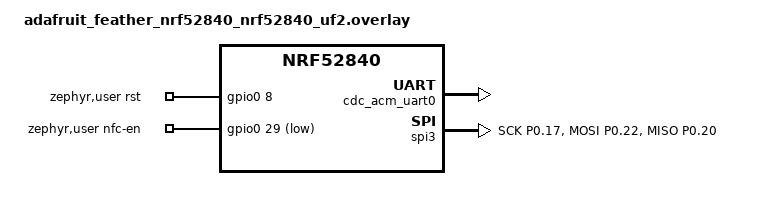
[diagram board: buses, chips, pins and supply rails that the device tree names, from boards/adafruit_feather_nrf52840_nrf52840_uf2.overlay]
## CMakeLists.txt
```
cmake_minimum_required(VERSION 3.20.0)
find_package(Zephyr REQUIRED HINTS $ENV{ZEPHYR_BASE})
project(ntag_writer)
target_sources(app PRIVATE src/main.c src/mfrc522.c)
```

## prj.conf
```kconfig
# NTAG NDEF writer — Elecrow nRF52840 + RC522 scanner board, USB CDC console.
# Build (NCS workspace, same as the scanner):
#   west build -d build_ntag -b adafruit_feather_nrf52840/nrf52840/uf2 tools/ntag-writer
# No Thread, no PM: this is a bench tool that lives on USB.

# Flash layout: app starts at 0x26000 (after Adafruit UF2/SoftDevice bootloader)
CONFIG_USE_DT_CODE_PARTITION=y

CONFIG_SPI=y
CONFIG_GPIO=y

CONFIG_PM=n
CONFIG_PM_DEVICE=n

CONFIG_SERIAL=y
CONFIG_CONSOLE=y
CONFIG_UART_CONSOLE=y
CONFIG_USB_DEVICE_STACK=y
CONFIG_USB_DEVICE_STACK_NEXT=n
CONFIG_USB_CDC_ACM=y
CONFIG_UART_LINE_CTRL=y
CONFIG_USB_DEVICE_PRODUCT="NTAG Writer"
CONFIG_USB_DEVICE_MANUFACTURER="rfid-thread-scanner"

CONFIG_MAIN_STACK_SIZE=4096

# The Elecrow clone may not have a 32 kHz crystal; the scanner builds never
# rely on one (MPSL clock control). Use the RC oscillator.
CONFIG_CLOCK_CONTROL_NRF_K32SRC_RC=y
```

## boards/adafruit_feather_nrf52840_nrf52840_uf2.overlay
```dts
/*
 * Elecrow Pro Micro nRF52840 scanner board, NTAG-writer subset of the main
 * scanner overlay (boards/ in the repo root):
 *   RC522:   SCK->P0.17  MOSI->P0.22  MISO->P0.20  CS->P0.09  RST->P0.08
 *   NFC-EN:  P0.29 (P-channel MOSFET, drive LOW = ON)
 * Console is USB CDC-ACM.
 */
#include <zephyr/dt-bindings/pinctrl/nrf-pinctrl.h>
#include <zephyr/dt-bindings/gpio/gpio.h>

/ {
	chosen {
		zephyr,console    = &cdc_acm_uart0;
		zephyr,shell-uart = &cdc_acm_uart0;
	};

	zephyr,user {
		rst-gpios    = <&gpio0  8 GPIO_ACTIVE_HIGH>;
		nfc-en-gpios = <&gpio0 29 GPIO_ACTIVE_LOW>;
	};
};

&zephyr_udc0 {
	cdc_acm_uart0: cdc_acm_uart0 {
		compatible = "zephyr,cdc-acm-uart";
	};
};

&qspi {
	status = "disabled";
};

&pinctrl {
	spi3_default: spi3_default {
		group1 {
			psels = <NRF_PSEL(SPIM_SCK,  0, 17)>,
				<NRF_PSEL(SPIM_MOSI, 0, 22)>,
				<NRF_PSEL(SPIM_MISO, 0, 20)>;
		};
	};
	spi3_sleep: spi3_sleep {
		group1 {
			psels = <NRF_PSEL(SPIM_SCK,  0, 17)>,
				<NRF_PSEL(SPIM_MOSI, 0, 22)>,
				<NRF_PSEL(SPIM_MISO, 0, 20)>;
			low-power-enable;
		};
	};
};

&spi3 {
	compatible = "nordic,nrf-spim";
	status = "okay";
	pinctrl-0 = <&spi3_default>;
	pinctrl-1 = <&spi3_sleep>;
	pinctrl-names = "default", "sleep";
	cs-gpios = <&gpio0 9 GPIO_ACTIVE_LOW>;
};

/* P0.09 is the RC522 CS; free the NFCT pins for GPIO (writes UICR once). */
&uicr {
	nfct-pins-as-gpios;
};

/* The Feather board dts enables spi1 with the legacy nrfx_spi driver, which
 * conflicts with USB CDC on this board (see the main overlay). Not used here. */
&spi1 {
	status = "disabled";
};

/* The board dts also adds a CDC-ACM port of its own (board_cdc_acm_uart),
 * which enumerates ahead of ours as ttyACM0. Drop it so there is one port.
 * (Takes effect on the next build/flash; v2 still has both.) */
&board_cdc_acm_uart {
	status = "disabled";
};
```

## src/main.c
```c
/*
 * NTAG NDEF-URL writer for the Elecrow nRF52840 + RC522 scanner board.
 *
 * Bench tool: sits on USB CDC-ACM, takes a URL over the console, and writes
 * an NDEF URI record onto every NTAG213/215/216 (or MIFARE Ultralight) tag
 * that is presented. Phones open the URL on tap. Not a Thread build.
 *
 * Console protocol (line based, machine-friendly first token):
 *   url <text>   set the URL           -> OK url=.. ndef=N fits213=y|n
 *   w            arm one write         -> WROTE uid=.. | ERR ..
 *   wl           write every tag       -> WROTE .. per tag, until 'x'
 *   r            read next tag         -> TAG .. / URL ..
 *   rl           read every tag
 *   f            force-format CC only  -> FORMATTED ..
 *   x            disarm
 *   s            status
 *   ?            help
 */
#include <zephyr/kernel.h>
#include <zephyr/drivers/spi.h>
#include <zephyr/drivers/gpio.h>
#include <zephyr/drivers/uart.h>
#include <zephyr/usb/usb_device.h>
#include <zephyr/sys/printk.h>
#include <string.h>
#include <ctype.h>
#include <stdio.h>
#include "mfrc522.h"

#define FW_VERSION      "1"
#define SPI_NODE        DT_NODELABEL(spi3)
#define POLL_MS         100
#define URL_MAX         200
#define NDEF_MAX        (URL_MAX + 16)
#define USER_PAGE0      4          /* Type 2 user memory starts at page 4 */
#define NTAG_MAX_USER   888        /* NTAG216 */

/* ── Hardware ────────────────────────────────────────────────────────────── */

static struct mfrc522_dev rc522 = {
	.spi = NULL,
	.spi_cfg = {
		.frequency = 1000000,
		.operation = SPI_WORD_SET(8) | SPI_TRANSFER_MSB | SPI_OP_MODE_MASTER,
	},
	.cs  = GPIO_DT_SPEC_GET_BY_IDX(DT_NODELABEL(spi3), cs_gpios, 0),
	.rst = GPIO_DT_SPEC_GET(DT_PATH(zephyr_user), rst_gpios),
};

static const struct gpio_dt_spec nfc_en =
	GPIO_DT_SPEC_GET(DT_PATH(zephyr_user), nfc_en_gpios);

static const struct device *usb_uart_dev;
static bool rc522_ok;

/* ── State ───────────────────────────────────────────────────────────────── */

enum mode { MODE_IDLE, MODE_WRITE, MODE_WRITE_LOOP, MODE_READ, MODE_READ_LOOP, MODE_FORMAT };
static enum mode mode = MODE_IDLE;
static char url[URL_MAX + 1];
static uint8_t ndef[NDEF_MAX];
static size_t ndef_len;
static unsigned writes_ok, writes_err;

static const char *mode_name(enum mode m)
{
	switch (m) {
	case MODE_IDLE:       return "idle";
	case MODE_WRITE:      return "write-once";
	case MODE_WRITE_LOOP: return "write-loop";
	case MODE_READ:       return "read-once";
	case MODE_READ_LOOP:  return "read-loop";
	case MODE_FORMAT:     return "format";
	}
	return "?";
}

/* ── NDEF ────────────────────────────────────────────────────────────────── */

/* NFC Forum URI record well-known prefixes (longest first so they win). */
static const struct { const char *s; uint8_t code; } uri_prefix[] = {
	{ "https://www.", 0x02 },
	{ "http://www.",  0x01 },
	{ "https://",     0x04 },
	{ "http://",      0x03 },
};

/* Build TLV-wrapped NDEF message with a single URI record. Returns length or -1. */
static int build_ndef(const char *u, uint8_t *out, size_t cap)
{
	uint8_t code = 0x00;
	const char *rest = u;
	for (size_t i = 0; i < ARRAY_SIZE(uri_prefix); i++) {
		size_t n = strlen(uri_prefix[i].s);
		if (strncmp(u, uri_prefix[i].s, n) == 0) {
			code = uri_prefix[i].code;
			rest = u + n;
			break;
		}
	}
	size_t rest_len = strlen(rest);
	size_t payload_len = 1 + rest_len;          /* prefix code + text */
	if (payload_len > 255) return -1;           /* short record only */
	size_t msg_len = 4 + payload_len;           /* hdr, type len, payload len, type */

	size_t p = 0;
	out[p++] = 0x03;                            /* NDEF Message TLV */
	if (msg_len < 0xFF) {
		out[p++] = (uint8_t)msg_len;
	} else {
		out[p++] = 0xFF;
		out[p++] = (uint8_t)(msg_len >> 8);
		out[p++] = (uint8_t)(msg_len & 0xFF);
	}
	if (p + msg_len + 1 > cap) return -1;
	out[p++] = 0xD1;                            /* MB|ME|SR, TNF=well-known */
	out[p++] = 0x01;                            /* type length */
	out[p++] = (uint8_t)payload_len;
	out[p++] = 'U';
	out[p++] = code;
	memcpy(&out[p], rest, rest_len);
	p += rest_len;
	out[p++] = 0xFE;                            /* Terminator TLV */
	return (int)p;
}

/* Parse a URI record out of user memory; returns true and fills `dst`. */
static bool parse_ndef_url(const uint8_t *mem, size_t len, char *dst, size_t cap)
{
	size_t p = 0;
	while (p < len) {
		uint8_t t = mem[p++];
		if (t == 0x00) continue;               /* NULL TLV */
		if (t == 0xFE) return false;           /* terminator */
		if (p >= len) return false;
		size_t l = mem[p++];
		if (l == 0xFF) {
			if (p + 2 > len) return false;
			l = (mem[p] << 8) | mem[p + 1];
			p += 2;
		}
		if (t != 0x03) { p += l; continue; }    /* skip non-NDEF TLV */
		if (p + l > len || l < 5) return false;
		const uint8_t *r = &mem[p];
		uint8_t hdr = r[0];
		if ((hdr & 0x07) != 0x01 || !(hdr & 0x10)) return false; /* well-known, SR */
		uint8_t tl = r[1];
		uint8_t pl = r[2];
		size_t off = 3 + ((hdr & 0x08) ? 1 : 0);      /* IL: id length byte */
		if (off + tl + pl > l || tl != 1 || r[off] != 'U' || pl < 1) return false;
		const uint8_t *pay = &r[off + tl];
		uint8_t code = pay[0];
		const char *pre = "";
		for (size_t i = 0; i < ARRAY_SIZE(uri_prefix); i++) {
			if (uri_prefix[i].code == code) pre = uri_prefix[i].s;
		}
		size_t pn = strlen(pre);
		size_t tn = pl - 1;
		if (pn + tn + 1 > cap) return false;
		memcpy(dst, pre, pn);
		memcpy(dst + pn, pay + 1, tn);
		dst[pn + tn] = '\0';
		return true;
	}
	return false;
}

/* ── Tag helpers ─────────────────────────────────────────────────────────── */

static void print_uid(const struct mfrc522_uid *uid)
{
	for (uint8_t i = 0; i < uid->size; i++) {
		printk("%s%02X", i ? ":" : "", uid->bytes[i]);
	}
}

/* User-memory size in bytes from GET_VERSION, else from the CC, else 48. */
static int tag_user_size(const uint8_t cc[4], const char **name)
{
	uint8_t ver[8];
	*name = "Type2";
	if (mfrc522_ntag_get_version(&rc522, ver) == MFRC_OK && ver[1] == 0x04) {
		switch (ver[6]) {
		case 0x0F: *name = "NTAG213"; return 144;
		case 0x11: *name = "NTAG215"; return 504;
		case 0x13: *name = "NTAG216"; return 888;
		default: break;
		}
	}
	if (cc[0] == 0xE1 && cc[2] != 0) {
		*name = "NDEF-CC";
		int sz = cc[2] * 8;
		return sz > NTAG_MAX_USER ? NTAG_MAX_USER : sz;
	}
	*name = "Ultralight?";
	return 48;
}

static int read_range(uint8_t page0, uint8_t *dst, size_t nbytes)
{
	uint8_t buf[16];
	size_t got = 0;
	uint8_t page = page0;
	while (got < nbytes) {
		int rc = mfrc522_ntag_read(&rc522, page, buf);
		if (rc != MFRC_OK) return rc;
		size_t take = nbytes - got < 16 ? nbytes - got : 16;
		memcpy(dst + got, buf, take);
		got += take;
		page += 4;
	}
	return MFRC_OK;
}

static int write_cc(int user_size)
{
	uint8_t cc[4] = { 0xE1, 0x10, (uint8_t)(user_size / 8), 0x00 };
	return mfrc522_ntag_write(&rc522, 3, cc);
}

/* ── Actions on a selected tag ──────────────────────────────────────────── */

static void do_read(const struct mfrc522_uid *uid)
{
	uint8_t hdr[16];
	if (mfrc522_ntag_read(&rc522, 0, hdr) != MFRC_OK) {
		printk("ERR read header failed\n");
		return;
	}
	const uint8_t *cc = &hdr[12];
	const char *name;
	int user = tag_user_size(cc, &name);
	printk("TAG uid="); print_uid(uid);
	printk(" sak=%02X type=%s user=%d cc=%02X%02X%02X%02X\n",
	       uid->sak, name, user, cc[0], cc[1], cc[2], cc[3]);

	static uint8_t mem[NTAG_MAX_USER];
	size_t n = user < (int)sizeof(mem) ? user : sizeof(mem);
	if (read_range(USER_PAGE0, mem, n) != MFRC_OK) {
		printk("ERR read user memory failed\n");
		return;
	}
	char found[URL_MAX + 1];
	if (parse_ndef_url(mem, n, found, sizeof(found))) {
		printk("URL %s\n", found);
	} else {
		printk("URL (none)\n");
	}
	printk("MEM");
	for (size_t i = 0; i < 32 && i < n; i++) printk(" %02X", mem[i]);
	printk("%s\n", n > 32 ? " ..." : "");
}

static void do_write(const struct mfrc522_uid *uid, bool format_only)
{
	if (uid->sak != 0x00) {
		printk("ERR uid="); print_uid(uid);
		printk(" sak=%02X is not a Type 2 tag (MIFARE Classic?)\n", uid->sak);
		writes_err++;
		return;
	}
	uint8_t hdr[16];
	if (mfrc522_ntag_read(&rc522, 0, hdr) != MFRC_OK) {
		printk("ERR read header failed\n");
		writes_err++;
		return;
	}
	const uint8_t *cc = &hdr[12];
	const char *name;
	int user = tag_user_size(cc, &name);

	if (format_only) {
		if (cc[0] == 0xE1) {
			printk("FORMATTED uid="); print_uid(uid);
			printk(" already (cc=%02X%02X%02X%02X)\n", cc[0], cc[1], cc[2], cc[3]);
			return;
		}
		if (write_cc(user) != MFRC_OK) {
			printk("ERR CC write failed\n");
			return;
		}
		printk("FORMATTED uid="); print_uid(uid);
		printk(" user=%d\n", user);
		return;
	}

	if (ndef_len == 0) {
		printk("ERR no url set\n");
		writes_err++;
		return;
	}
	if ((int)ndef_len > user) {
		printk("ERR ndef %u bytes > %s user %d\n", (unsigned)ndef_len, name, user);
		writes_err++;
		return;
	}
	/* CC is OTP (bits only go 0->1). Only touch it when it is blank. */
	if (cc[0] != 0xE1) {
		if (cc[0] == 0 && cc[1] == 0 && cc[2] == 0 && cc[3] == 0) {
			if (write_cc(user) != MFRC_OK) {
				printk("ERR CC write failed\n");
				writes_err++;
				return;
			}
		} else {
			printk("ERR cc=%02X%02X%02X%02X not NDEF and not blank; refusing\n",
			       cc[0], cc[1], cc[2], cc[3]);
			writes_err++;
			return;
		}
	}

	/* Write pages, zero-padded to a 4-byte boundary. */
	size_t pages = (ndef_len + 3) / 4;
	for (size_t i = 0; i < pages; i++) {
		uint8_t d[4] = { 0, 0, 0, 0 };
		size_t off = i * 4;
		size_t take = ndef_len - off < 4 ? ndef_len - off : 4;
		memcpy(d, &ndef[off], take);
		if (mfrc522_ntag_write(&rc522, USER_PAGE0 + i, d) != MFRC_OK) {
			printk("ERR write page %u failed\n", (unsigned)(USER_PAGE0 + i));
			writes_err++;
			return;
		}
	}

	/* Verify. */
	static uint8_t back[NDEF_MAX + 16];
	size_t vlen = pages * 4;
	if (read_range(USER_PAGE0, back, vlen) != MFRC_OK ||
	    memcmp(back, ndef, ndef_len) != 0) {
		printk("ERR verify mismatch\n");
		writes_err++;
		return;
	}
	writes_ok++;
	printk("WROTE uid="); print_uid(uid);
	printk(" type=%s bytes=%u pages=%u n=%u\n", name, (unsigned)ndef_len,
	       (unsigned)pages, writes_ok);
}

/* ── Console ─────────────────────────────────────────────────────────────── */

static void print_help(void)
{
	printk("commands:\n"
	       "  url <text>  set URL to write\n"
	       "  w           write next tag once\n"
	       "  wl          write every tag until x\n"
	       "  r / rl      read next tag / every tag\n"
	       "  f           format CC on next tag (blank tags only)\n"
	       "  x           disarm\n"
	       "  s           status\n");
}

static void print_status(void)
{
	printk("STATUS mode=%s rc522=%s url=%s ndef=%u ok=%u err=%u\n",
	       mode_name(mode), rc522_ok ? "ok" : "missing",
	       url[0] ? url : "(none)", (unsigned)ndef_len, writes_ok, writes_err);
}

static void handle_cmd(char *line)
{
	/* trim */
	while (*line && isspace((unsigned char)*line)) line++;
	char *end = line + strlen(line);
	while (end > line && isspace((unsigned char)end[-1])) *--end = '\0';
	if (!*line) return;

	if (strncmp(line, "url ", 4) == 0 || strncmp(line, "u ", 2) == 0) {
		const char *arg = line + (line[1] == ' ' ? 2 : 4);
		while (*arg == ' ') arg++;
		if (strlen(arg) > URL_MAX) {
			printk("ERR url longer than %d\n", URL_MAX);
			return;
		}
		int n = build_ndef(arg, ndef, sizeof(ndef));
		if (n < 0) {
			printk("ERR url does not fit an NDEF short record\n");
			return;
		}
		strcpy(url, arg);
		ndef_len = (size_t)n;
		printk("OK url=%s ndef=%u fits213=%c fits215=%c\n", url, (unsigned)ndef_len,
		       ndef_len <= 144 ? 'y' : 'n', ndef_len <= 504 ? 'y' : 'n');
	} else if (strcmp(line, "w") == 0) {
		if (!ndef_len) { printk("ERR no url set\n"); return; }
		mode = MODE_WRITE;  printk("OK armed write-once; present a tag\n");
	} else if (strcmp(line, "wl") == 0) {
		if (!ndef_len) { printk("ERR no url set\n"); return; }
		mode = MODE_WRITE_LOOP; printk("OK armed write-loop; present tags, x to stop\n");
	} else if (strcmp(line, "r") == 0) {
		mode = MODE_READ;   printk("OK armed read-once\n");
	} else if (strcmp(line, "rl") == 0) {
		mode = MODE_READ_LOOP; printk("OK armed read-loop\n");
	} else if (strcmp(line, "f") == 0) {
		mode = MODE_FORMAT; printk("OK armed format-once\n");
	} else if (strcmp(line, "x") == 0) {
		mode = MODE_IDLE;   printk("OK idle\n");
	} else if (strcmp(line, "s") == 0) {
		print_status();
	} else if (strcmp(line, "?") == 0 || strcmp(line, "help") == 0) {
		print_help();
	} else {
		printk("ERR unknown command: %s\n", line);
	}
}

#define CONSOLE_STACK 2048
K_THREAD_STACK_DEFINE(console_stack, CONSOLE_STACK);
static struct k_thread console_thread_data;

static void console_thread(void *a, void *b, void *c)
{
	ARG_UNUSED(a); ARG_UNUSED(b); ARG_UNUSED(c);
	char line[URL_MAX + 8];
	int pos = 0;
	while (1) {
		uint8_t ch;
		if (uart_poll_in(usb_uart_dev, &ch) == 0) {
			if (ch == '\r' || ch == '\n') {
				line[pos] = '\0';
				if (pos > 0) {
					handle_cmd(line);
					pos = 0;
				}
			} else if ((ch == '\b' || ch == 0x7f) && pos > 0) {
				pos--;
			} else if (pos < (int)sizeof(line) - 1 && ch >= 0x20) {
				line[pos++] = ch;
			}
		} else {
			k_sleep(K_MSEC(5));
		}
	}
}

/* ── Main ────────────────────────────────────────────────────────────────── */

int main(void)
{
	rc522.spi = DEVICE_DT_GET(SPI_NODE);
	usb_uart_dev = DEVICE_DT_GET(DT_CHOSEN(zephyr_console));
	usb_enable(NULL);

	/* NFC rail on (P-FET, active low). */
	if (gpio_is_ready_dt(&nfc_en)) {
		gpio_pin_configure_dt(&nfc_en, GPIO_OUTPUT_ACTIVE);
		k_sleep(K_MSEC(20));
	}

	rc522_ok = false;
	if (mfrc522_init(&rc522) == 0) {
		uint8_t ver = mfrc522_read_version(&rc522);
		rc522_ok = (ver != 0x00 && ver != 0xFF);
	}

	k_thread_create(&console_thread_data, console_stack,
			K_THREAD_STACK_SIZEOF(console_stack),
			console_thread, NULL, NULL, NULL,
			K_PRIO_PREEMPT(5), 0, K_NO_WAIT);

	/* Give the host a moment to open the port, then announce. */
	k_sleep(K_SECONDS(2));
	printk("\nREADY ntag-writer v" FW_VERSION " rc522=%s (0x%02X)\n",
	       rc522_ok ? "ok" : "MISSING", mfrc522_read_version(&rc522));
	print_help();

	while (1) {
		if (mode == MODE_IDLE || !rc522_ok) {
			k_sleep(K_MSEC(POLL_MS));
			continue;
		}
		if (!mfrc522_is_card_present(&rc522)) {
			k_sleep(K_MSEC(POLL_MS));
			continue;
		}
		struct mfrc522_uid uid;
		if (mfrc522_read_card_serial(&rc522, &uid) != MFRC_OK) {
			k_sleep(K_MSEC(POLL_MS));
			continue;
		}

		enum mode m = mode;
		switch (m) {
		case MODE_WRITE:
		case MODE_WRITE_LOOP:
			do_write(&uid, false);
			break;
		case MODE_FORMAT:
			do_write(&uid, true);
			break;
		case MODE_READ:
		case MODE_READ_LOOP:
			do_read(&uid);
			break;
		default:
			break;
		}
		/* HLTA: a halted tag ignores REQA, so it is not re-processed until
		 * it leaves the field and comes back. */
		mfrc522_halt(&rc522);

		if (m == MODE_WRITE || m == MODE_READ || m == MODE_FORMAT) {
			mode = MODE_IDLE;
			printk("OK idle\n");
		}
		k_sleep(K_MSEC(300));
	}
	return 0;
}
```

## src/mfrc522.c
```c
#include <string.h>
#include "mfrc522.h"
#include <zephyr/logging/log.h>
LOG_MODULE_REGISTER(mfrc522, LOG_LEVEL_DBG);

/* ── Low-level SPI register access ────────────────────────────────────── */
/* All accessors return 0 or a negative errno from the SPI driver, so a
 * failed bus transaction is distinguishable from a register that
 * legitimately reads 0x00. */

static int reg_write(struct mfrc522_dev *dev, uint8_t reg, uint8_t val)
{
	uint8_t tx[2] = { reg & 0x7E, val };
	struct spi_buf     buf    = { .buf = tx, .len = 2 };
	struct spi_buf_set tx_set = { .buffers = &buf, .count = 1 };
	gpio_pin_set_dt(&dev->cs, 1);  /* assert CS (active-low: logical 1 = physical LOW) */
	int rc = spi_write(dev->spi, &dev->spi_cfg, &tx_set);
	gpio_pin_set_dt(&dev->cs, 0);  /* deassert CS */
	return rc;
}

static int reg_read(struct mfrc522_dev *dev, uint8_t reg, uint8_t *val)
{
	uint8_t tx[2] = { 0x80 | reg, 0 };
	uint8_t rx[2] = { 0, 0 };
	struct spi_buf     tbuf   = { .buf = tx, .len = 2 };
	struct spi_buf     rbuf   = { .buf = rx, .len = 2 };
	struct spi_buf_set tx_set = { .buffers = &tbuf, .count = 1 };
	struct spi_buf_set rx_set = { .buffers = &rbuf, .count = 1 };
	gpio_pin_set_dt(&dev->cs, 1);  /* assert CS */
	int rc = spi_transceive(dev->spi, &dev->spi_cfg, &tx_set, &rx_set);
	gpio_pin_set_dt(&dev->cs, 0);  /* deassert CS */
	*val = rx[1];
	return rc;
}

static int reg_set_bits(struct mfrc522_dev *dev, uint8_t reg, uint8_t mask)
{
	uint8_t val;
	int rc = reg_read(dev, reg, &val);
	if (rc < 0) {
		return rc;
	}
	return reg_write(dev, reg, val | mask);
}

static int reg_clear_bits(struct mfrc522_dev *dev, uint8_t reg, uint8_t mask)
{
	uint8_t val;
	int rc = reg_read(dev, reg, &val);
	if (rc < 0) {
		return rc;
	}
	return reg_write(dev, reg, val & ~mask);
}

static int fifo_write(struct mfrc522_dev *dev, const uint8_t *data, uint8_t len)
{
	for (uint8_t i = 0; i < len; i++) {
		int rc = reg_write(dev, MFRC_FIFODataReg, data[i]);
		if (rc < 0) {
			return rc;
		}
	}
	return 0;
}

/* ── CRC helper ────────────────────────────────────────────────────────── */

static int pcd_calc_crc(struct mfrc522_dev *dev, const uint8_t *data, uint8_t len, uint8_t crc[2])
{
	if (reg_write(dev, MFRC_CommandReg, PCD_Idle) < 0 ||
	    reg_write(dev, MFRC_DivIrqReg, 0x04) < 0 ||       /* clear CRCIRq */
	    reg_set_bits(dev, MFRC_FIFOLevelReg, 0x80) < 0 || /* flush FIFO */
	    fifo_write(dev, data, len) < 0 ||
	    reg_write(dev, MFRC_CommandReg, PCD_CalcCRC) < 0) {
		return MFRC_BUS_ERROR;
	}

	int64_t deadline = k_uptime_get() + 50;
	while (k_uptime_get() < deadline) {
		uint8_t irq;
		if (reg_read(dev, MFRC_DivIrqReg, &irq) < 0) {
			return MFRC_BUS_ERROR;
		}
		if (irq & 0x04) {
			if (reg_write(dev, MFRC_CommandReg, PCD_Idle) < 0 ||
			    reg_read(dev, MFRC_CRCResultRegL, &crc[0]) < 0 ||
			    reg_read(dev, MFRC_CRCResultRegH, &crc[1]) < 0) {
				return MFRC_BUS_ERROR;
			}
			return MFRC_OK;
		}
		k_sleep(K_MSEC(1)); /* yield — don't busy-spin between register reads */
	}
	return MFRC_TIMEOUT;
}

/* ── Transceive ────────────────────────────────────────────────────────── */

static int pcd_transceive(struct mfrc522_dev *dev,
			   const uint8_t *tx_data, uint8_t tx_len,
			   uint8_t *rx_data, uint8_t *rx_len,
			   uint8_t *valid_bits)
{
	if (reg_write(dev, MFRC_CommandReg, PCD_Idle) < 0 ||
	    reg_set_bits(dev, MFRC_FIFOLevelReg, 0x80) < 0 ||
	    fifo_write(dev, tx_data, tx_len) < 0 ||
	    reg_write(dev, MFRC_BitFramingReg, valid_bits ? *valid_bits : 0) < 0 ||
	    /* Clear stale IRQ flags (Set1=0 → clear the bits that are set in bits[6:0]) */
	    reg_write(dev, MFRC_ComIrqReg, 0x7F) < 0 ||
	    reg_write(dev, MFRC_CommandReg, PCD_Transceive) < 0 ||
	    reg_set_bits(dev, MFRC_BitFramingReg, 0x80) < 0) { /* StartSend */
		return MFRC_BUS_ERROR;
	}

	/* Wait for completion (timeout ~25ms via timer config) */
	int64_t deadline = k_uptime_get() + 50;
	uint8_t irq = 0;
	do {
		if (reg_read(dev, MFRC_ComIrqReg, &irq) < 0) {
			return MFRC_BUS_ERROR;
		}
		if (irq & 0x30) break; /* RxIRq or IdleIRq */
		if (irq & 0x01) return MFRC_TIMEOUT; /* TimerIRq */
		k_sleep(K_MSEC(1)); /* yield — don't busy-spin between register reads */
	} while (k_uptime_get() < deadline);

	if (!(irq & 0x30)) return MFRC_TIMEOUT;

	uint8_t err;
	if (reg_read(dev, MFRC_ErrorReg, &err) < 0) {
		return MFRC_BUS_ERROR;
	}
	if (err & 0x13) return MFRC_ERROR; /* BufferOvfl, ParityErr, ProtocolErr */
	if (err & 0x08) return MFRC_COLLISION;

	uint8_t n;
	if (reg_read(dev, MFRC_FIFOLevelReg, &n) < 0) {
		return MFRC_BUS_ERROR;
	}
	if (rx_len && rx_data) {
		uint8_t copy = (n < *rx_len) ? n : *rx_len;
		*rx_len = copy;
		for (uint8_t i = 0; i < copy; i++) {
			if (reg_read(dev, MFRC_FIFODataReg, &rx_data[i]) < 0) {
				return MFRC_BUS_ERROR;
			}
		}
	}
	if (valid_bits) {
		uint8_t ctrl;
		if (reg_read(dev, MFRC_ControlReg, &ctrl) < 0) {
			return MFRC_BUS_ERROR;
		}
		*valid_bits = ctrl & 0x07;
	}
	return MFRC_OK;
}

/* ── Public API ────────────────────────────────────────────────────────── */

int mfrc522_init(struct mfrc522_dev *dev)
{
	if (!device_is_ready(dev->spi)) return -ENODEV;

	/* Configure CS as output deasserted (inactive = physical HIGH for active-low) */
	gpio_pin_configure_dt(&dev->cs, GPIO_OUTPUT_INACTIVE);

	/* Hardware reset via RST pin */
	gpio_pin_configure_dt(&dev->rst, GPIO_OUTPUT_ACTIVE);
	k_sleep(K_MSEC(10));
	gpio_pin_set_dt(&dev->rst, 0);
	k_sleep(K_MSEC(50));
	gpio_pin_set_dt(&dev->rst, 1);
	k_sleep(K_MSEC(50));

	/* Soft reset */
	if (reg_write(dev, MFRC_CommandReg, PCD_SoftReset) < 0) {
		return -EIO;
	}
	k_sleep(K_MSEC(50));

	/* Configure timer: auto, prescaler=169 → ~40kHz, reload=1000 → 25ms */
	if (reg_write(dev, MFRC_TModeReg,      0x80) < 0 ||
	    reg_write(dev, MFRC_TPrescalerReg, 0xA9) < 0 ||
	    reg_write(dev, MFRC_TReloadRegH,   0x03) < 0 ||
	    reg_write(dev, MFRC_TReloadRegL,   0xE8) < 0 ||
	    reg_write(dev, MFRC_TxASKReg, 0x40) < 0 ||  /* 100% ASK */
	    reg_write(dev, MFRC_ModeReg,  0x3D) < 0) {  /* CRC preset 6363h */
		return -EIO;
	}

	/* Antenna on */
	uint8_t tx;
	if (reg_read(dev, MFRC_TxControlReg, &tx) < 0) {
		return -EIO;
	}
	if (!(tx & 0x03)) {
		if (reg_set_bits(dev, MFRC_TxControlReg, 0x03) < 0) {
			return -EIO;
		}
	}
	return 0;
}

uint8_t mfrc522_read_version(struct mfrc522_dev *dev)
{
	uint8_t ver = 0;

	/* A bus error reads as 0x00, which callers already treat as "no reader" */
	if (reg_read(dev, MFRC_VersionReg, &ver) < 0) {
		return 0x00;
	}
	return ver;
}

/* SoftPowerDown: ~26mA antenna current → ~10µA. Antenna also goes off. */
void mfrc522_sleep(struct mfrc522_dev *dev)
{
	reg_clear_bits(dev, MFRC_TxControlReg, 0x03);
	reg_write(dev, MFRC_CommandReg, 0x10 | PCD_Idle);
}

void mfrc522_wake(struct mfrc522_dev *dev)
{
	reg_write(dev, MFRC_CommandReg, PCD_Idle);
	/* Bit clears automatically once oscillator stable; poll briefly */
	for (int i = 0; i < 50; i++) {
		uint8_t cmd;
		if (reg_read(dev, MFRC_CommandReg, &cmd) == 0 && !(cmd & 0x10)) {
			break;
		}
		k_sleep(K_MSEC(1));
	}
	reg_set_bits(dev, MFRC_TxControlReg, 0x03);
}

bool mfrc522_is_card_present(struct mfrc522_dev *dev)
{
	/* Reset baud rates (required before REQA per MFRC522 datasheet) */
	if (reg_write(dev, MFRC_TxModeReg,  0x00) < 0 ||
	    reg_write(dev, MFRC_RxModeReg,  0x00) < 0 ||
	    reg_write(dev, MFRC_ModWidthReg, 0x26) < 0) {
		return false;
	}

	reg_clear_bits(dev, MFRC_CollReg, 0x80);
	uint8_t cmd     = PICC_CMD_REQA;
	uint8_t atqa[2] = { 0, 0 };
	uint8_t atqa_len = 2;
	uint8_t vbits    = 7; /* Short frame: 7 bits */

	int rc = pcd_transceive(dev, &cmd, 1, atqa, &atqa_len, &vbits);
	return (rc == MFRC_OK || rc == MFRC_COLLISION);
}

int mfrc522_read_card_serial(struct mfrc522_dev *dev, struct mfrc522_uid *uid)
{
	/* ISO 14443A anti-collision + SELECT, handles 4-byte and 7-byte UIDs */
	static const uint8_t cl_cmd[2] = { PICC_CMD_ANTICOLL, PICC_CMD_SEL_CL2 };
	uint8_t buf[9];
	uint8_t buf_len, vbits;
	int rc;
	uint8_t uid_idx = 0;

	uid->size = 0;

	for (int cl = 0; cl < 2; cl++) {
		/* Anti-collision */
		reg_clear_bits(dev, MFRC_CollReg, 0x80);
		reg_write(dev, MFRC_BitFramingReg, 0x00);

		buf[0] = cl_cmd[cl];
		buf[1] = 0x20;
		buf_len = 5;
		vbits   = 0;

		rc = pcd_transceive(dev, buf, 2, &buf[2], &buf_len, &vbits);
		if (rc != MFRC_OK && rc != MFRC_COLLISION) return rc;
		if (buf_len < 5) return MFRC_ERROR;

		/* BCC: XOR of all 5 bytes must be 0 */
		if ((buf[2] ^ buf[3] ^ buf[4] ^ buf[5] ^ buf[6]) != 0) return MFRC_ERROR;

		/* SELECT: send [CLx, 0x70, uid0..3, bcc, crc_l, crc_h] */
		buf[1] = 0x70;
		uint8_t crc[2];
		rc = pcd_calc_crc(dev, buf, 7, crc);
		if (rc != MFRC_OK) return rc;
		buf[7] = crc[0];
		buf[8] = crc[1];

		uint8_t sak_buf[3] = {0};
		uint8_t sak_len = 3;
		uint8_t sak_vbits = 0;
		rc = pcd_transceive(dev, buf, 9, sak_buf, &sak_len, &sak_vbits);
		if (rc != MFRC_OK) return rc;

		uint8_t sak = sak_buf[0];
		uid->sak = sak;

		/* Copy UID bytes from this cascade level, skipping cascade tag (0x88) */
		bool has_ct  = (buf[2] == 0x88);
		uint8_t start = has_ct ? 1 : 0;
		uint8_t count = has_ct ? 3 : 4;
		for (uint8_t i = 0; i < count && uid_idx < MFRC_UID_MAX_BYTES; i++) {
			uid->bytes[uid_idx++] = buf[2 + start + i];
		}
		uid->size = uid_idx;

		/* SAK bit 2 set = UID incomplete, continue to next cascade level */
		if (!(sak & 0x04)) break;
	}

	return MFRC_OK;
}

/* ── NTAG2xx / Ultralight ──────────────────────────────────────────────── */

/* Send cmd+args with CRC_A appended; expect exactly `want` data bytes + CRC. */
static int ul_cmd(struct mfrc522_dev *dev, const uint8_t *cmd, uint8_t cmd_len,
		  uint8_t *out, uint8_t want)
{
	uint8_t tx[8];
	uint8_t crc[2];
	if (cmd_len + 2 > sizeof(tx)) return MFRC_ERROR;
	memcpy(tx, cmd, cmd_len);
	int rc = pcd_calc_crc(dev, tx, cmd_len, crc);
	if (rc != MFRC_OK) return rc;
	tx[cmd_len] = crc[0];
	tx[cmd_len + 1] = crc[1];

	uint8_t rx[18];
	uint8_t rx_len = sizeof(rx);
	uint8_t vbits = 0;
	rc = pcd_transceive(dev, tx, cmd_len + 2, rx, &rx_len, &vbits);
	if (rc != MFRC_OK) return rc;
	if (rx_len != want + 2) {
		/* NAK is a 4-bit reply (0x0, 0x1, 0x4, 0x5) */
		return (rx_len == 1 && vbits == 4) ? MFRC_ERROR : MFRC_TIMEOUT;
	}
	/* Verify CRC_A on the payload */
	rc = pcd_calc_crc(dev, rx, want, crc);
	if (rc != MFRC_OK) return rc;
	if (rx[want] != crc[0] || rx[want + 1] != crc[1]) return MFRC_ERROR;
	memcpy(out, rx, want);
	return MFRC_OK;
}

int mfrc522_ntag_read(struct mfrc522_dev *dev, uint8_t page, uint8_t out[16])
{
	uint8_t cmd[2] = { PICC_CMD_UL_READ, page };
	return ul_cmd(dev, cmd, 2, out, 16);
}

int mfrc522_ntag_get_version(struct mfrc522_dev *dev, uint8_t out[8])
{
	uint8_t cmd[1] = { PICC_CMD_GET_VER };
	return ul_cmd(dev, cmd, 1, out, 8);
}

int mfrc522_ntag_write(struct mfrc522_dev *dev, uint8_t page, const uint8_t data[4])
{
	uint8_t tx[8] = { PICC_CMD_UL_WRITE, page, data[0], data[1], data[2], data[3] };
	uint8_t crc[2];
	int rc = pcd_calc_crc(dev, tx, 6, crc);
	if (rc != MFRC_OK) return rc;
	tx[6] = crc[0];
	tx[7] = crc[1];

	/* Reply is a 4-bit ACK (0xA) or NAK. */
	uint8_t rx[2] = { 0 };
	uint8_t rx_len = sizeof(rx);
	uint8_t vbits = 0;
	rc = pcd_transceive(dev, tx, 8, rx, &rx_len, &vbits);
	if (rc != MFRC_OK) return rc;
	if (rx_len != 1 || vbits != 4) return MFRC_ERROR;
	return ((rx[0] & 0x0F) == 0x0A) ? MFRC_OK : MFRC_ERROR;
}

void mfrc522_halt(struct mfrc522_dev *dev)
{
	uint8_t tx[4] = { PICC_CMD_HLTA, 0x00, 0, 0 };
	uint8_t crc[2];
	if (pcd_calc_crc(dev, tx, 2, crc) != MFRC_OK) return;
	tx[2] = crc[0];
	tx[3] = crc[1];
	/* HLTA is answered by silence; a timeout is the success case. */
	(void)pcd_transceive(dev, tx, 4, NULL, NULL, NULL);
}
```

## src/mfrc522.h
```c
#pragma once
#include <zephyr/kernel.h>
#include <zephyr/drivers/spi.h>
#include <zephyr/drivers/gpio.h>
#include <stdint.h>
#include <stdbool.h>

/* RC522 register addresses (pre-shifted left 1 per MFRC522 SPI protocol) */
#define MFRC_CommandReg    (0x01 << 1)
#define MFRC_ComIEnReg     (0x02 << 1)
#define MFRC_ComIrqReg     (0x04 << 1)
#define MFRC_ErrorReg      (0x06 << 1)
#define MFRC_Status2Reg    (0x08 << 1)
#define MFRC_FIFODataReg   (0x09 << 1)
#define MFRC_FIFOLevelReg  (0x0A << 1)
#define MFRC_ControlReg    (0x0C << 1)
#define MFRC_BitFramingReg (0x0D << 1)
#define MFRC_CollReg       (0x0E << 1)
#define MFRC_ModeReg       (0x11 << 1)
#define MFRC_TxModeReg     (0x12 << 1)
#define MFRC_RxModeReg     (0x13 << 1)
#define MFRC_TxControlReg  (0x14 << 1)
#define MFRC_TxASKReg      (0x15 << 1)
#define MFRC_ModWidthReg   (0x24 << 1)
#define MFRC_TModeReg      (0x2A << 1)
#define MFRC_TPrescalerReg (0x2B << 1)
#define MFRC_TReloadRegH   (0x2C << 1)
#define MFRC_TReloadRegL   (0x2D << 1)
#define MFRC_DivIrqReg     (0x05 << 1)
#define MFRC_CRCResultRegH (0x21 << 1)
#define MFRC_CRCResultRegL (0x22 << 1)
#define MFRC_VersionReg    (0x37 << 1)

/* PCD commands */
#define PCD_Idle           0x00
#define PCD_CalcCRC        0x03
#define PCD_Transceive     0x0C
#define PCD_SoftReset      0x0F

/* PICC commands */
#define PICC_CMD_REQA      0x26
#define PICC_CMD_ANTICOLL  0x93  /* CL1 anti-collision / select */
#define PICC_CMD_SEL_CL2   0x95  /* CL2 anti-collision / select */

/* Status codes */
#define MFRC_OK            0
#define MFRC_ERROR         1
#define MFRC_TIMEOUT       2
#define MFRC_COLLISION     3
#define MFRC_NO_ROOM       4
#define MFRC_BUS_ERROR     5   /* SPI transaction failed (nRF driver error, not chip) */

#define MFRC_UID_MAX_BYTES 10

struct mfrc522_uid {
	uint8_t size;
	uint8_t bytes[MFRC_UID_MAX_BYTES];
	uint8_t sak;
};

struct mfrc522_dev {
	const struct device *spi;
	struct spi_config spi_cfg;
	struct gpio_dt_spec cs;   /* manually controlled CS (bypasses SPI driver CS) */
	struct gpio_dt_spec rst;
};

int  mfrc522_init(struct mfrc522_dev *dev);
uint8_t mfrc522_read_version(struct mfrc522_dev *dev);
bool mfrc522_is_card_present(struct mfrc522_dev *dev);
int  mfrc522_read_card_serial(struct mfrc522_dev *dev, struct mfrc522_uid *uid);
void mfrc522_sleep(struct mfrc522_dev *dev);
void mfrc522_wake(struct mfrc522_dev *dev);

/* ── NTAG2xx / MIFARE Ultralight (ISO14443-3A Type 2) commands ─────────── */
#define PICC_CMD_HLTA      0x50
#define PICC_CMD_UL_READ   0x30  /* 4 pages (16 bytes) from page N */
#define PICC_CMD_UL_WRITE  0xA2  /* 4 bytes to page N */
#define PICC_CMD_GET_VER   0x60  /* NTAG21x GET_VERSION, 8 bytes */

/* Card must already be selected (mfrc522_read_card_serial). */
int mfrc522_ntag_read(struct mfrc522_dev *dev, uint8_t page, uint8_t out[16]);
int mfrc522_ntag_write(struct mfrc522_dev *dev, uint8_t page, const uint8_t data[4]);
int mfrc522_ntag_get_version(struct mfrc522_dev *dev, uint8_t out[8]);
void mfrc522_halt(struct mfrc522_dev *dev);
```
